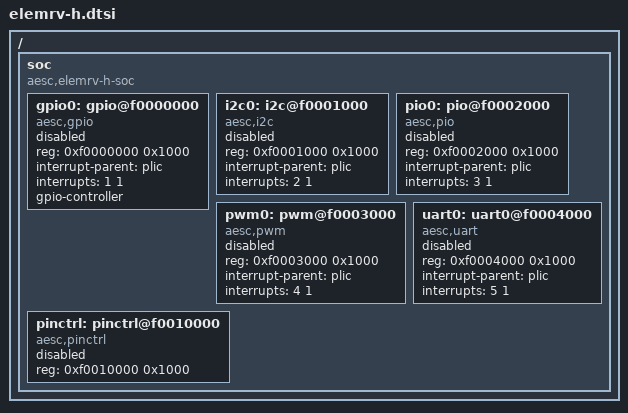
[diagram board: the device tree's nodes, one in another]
/*
 * Copyright (c) 2026 Aesc Silicon
 *
 * SPDX-License-Identifier: Apache-2.0
 */

#include <aesc/hydrogen.dtsi>

/ {
	#address-cells = <1>;
	#size-cells = <1>;

	soc {
		#address-cells = <1>;
		#size-cells = <1>;
		compatible = "aesc,elemrv-h-soc", "simple-bus";
		ranges;

		gpio0: gpio@f0000000 {
			compatible = "aesc,gpio";
			reg = <0xf0000000 0x1000>;
			interrupt-parent = <&plic>;
			interrupts = <1 1>;
			gpio-controller;
			#gpio-cells = <2>;
			status = "disabled";
		};

		i2c0: i2c@f0001000 {
			compatible = "aesc,i2c";
			reg = <0xf0001000 0x1000>;
			interrupt-parent = <&plic>;
			interrupts = <2 1>;
			status = "disabled";
		};

		pio0: pio@f0002000 {
			compatible = "aesc,pio";
			reg = <0xf0002000 0x1000>;
			interrupt-parent = <&plic>;
			interrupts = <3 1>;
			status = "disabled";
		};

		pwm0: pwm@f0003000 {
			compatible = "aesc,pwm";
			reg = <0xf0003000 0x1000>;
			interrupt-parent = <&plic>;
			interrupts = <4 1>;
			#pwm-cells = <3>;
			status = "disabled";
		};

		uart0: uart0@f0004000 {
			compatible = "aesc,uart";
			reg = <0xf0004000 0x1000>;
			interrupt-parent = <&plic>;
			interrupts = <5 1>;
			status = "disabled";
		};

		pinctrl: pinctrl@f0010000 {
			compatible = "aesc,pinctrl";
			reg = <0xf0010000 0x1000>;
			status = "disabled";
		};
	};
};
